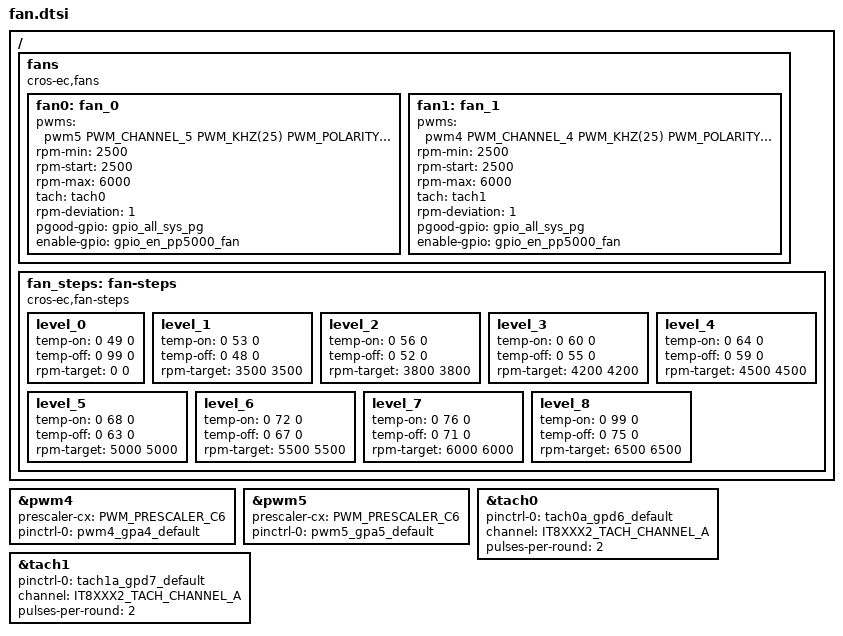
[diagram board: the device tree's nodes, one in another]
/* Copyright 2025 The ChromiumOS Authors
 * Use of this source code is governed by a BSD-style license that can be
 * found in the LICENSE file.
 */
/ {
	fans {
		compatible = "cros-ec,fans";

		fan0: fan_0 {
			pwms = <&pwm5 PWM_CHANNEL_5 PWM_KHZ(25) PWM_POLARITY_NORMAL>;
			rpm-min = <2500>;
			rpm-start = <2500>;
			rpm-max = <6000>;
			tach = <&tach0>;
			rpm-deviation = <1>;
			pgood-gpio = <&gpio_all_sys_pg>;
			enable-gpio = <&gpio_en_pp5000_fan>;
		};
		fan1: fan_1 {
			pwms = <&pwm4 PWM_CHANNEL_4 PWM_KHZ(25) PWM_POLARITY_NORMAL>;
			rpm-min = <2500>;
			rpm-start = <2500>;
			rpm-max = <6000>;
			tach = <&tach1>;
			rpm-deviation = <1>;
			pgood-gpio = <&gpio_all_sys_pg>;
			enable-gpio = <&gpio_en_pp5000_fan>;
		};
	};

	fan_steps: fan-steps {
		compatible = "cros-ec,fan-steps";
		level_0 {
			temp-on = <0 49 0>;
			temp-off = <0 99 0>;
			rpm-target = <0 0>;
		};
		level_1 {
			temp-on = <0 53 0>;
			temp-off = <0 48 0>;
			rpm-target = <3500 3500>;
		};
		level_2 {
			temp-on = <0 56 0>;
			temp-off = <0 52 0>;
			rpm-target = <3800 3800>;
		};
		level_3 {
			temp-on = <0 60 0>;
			temp-off = <0 55 0>;
			rpm-target = <4200 4200>;
		};
		level_4 {
			temp-on = <0 64 0>;
			temp-off = <0 59 0>;
			rpm-target = <4500 4500>;
		};
		level_5 {
			temp-on = <0 68 0>;
			temp-off = <0 63 0>;
			rpm-target = <5000 5000>;
		};
		level_6 {
			temp-on = <0 72 0>;
			temp-off = <0 67 0>;
			rpm-target = <5500 5500>;
		};
		level_7 {
			temp-on = <0 76 0>;
			temp-off = <0 71 0>;
			rpm-target = <6000 6000>;
		};
		level_8 {
			temp-on = <0 99 0>;
			temp-off = <0 75 0>;
			rpm-target = <6500 6500>;
		};
	};
};

&pwm4 {
	status = "okay";
	prescaler-cx = <PWM_PRESCALER_C6>;
	pinctrl-0 = <&pwm4_gpa4_default>;
	pinctrl-names = "default";
};

&pwm5 {
	status = "okay";
	prescaler-cx = <PWM_PRESCALER_C6>;
	pinctrl-0 = <&pwm5_gpa5_default>;
	pinctrl-names = "default";
};

&tach0 {
	status = "okay";
	pinctrl-0 = <&tach0a_gpd6_default>;
	pinctrl-names = "default";
	channel = <IT8XXX2_TACH_CHANNEL_A>;
	pulses-per-round = <2>;
};

&tach1 {
	status = "okay";
	pinctrl-0 = <&tach1a_gpd7_default>;
	pinctrl-names = "default";
	channel = <IT8XXX2_TACH_CHANNEL_A>;
	pulses-per-round = <2>;
};
